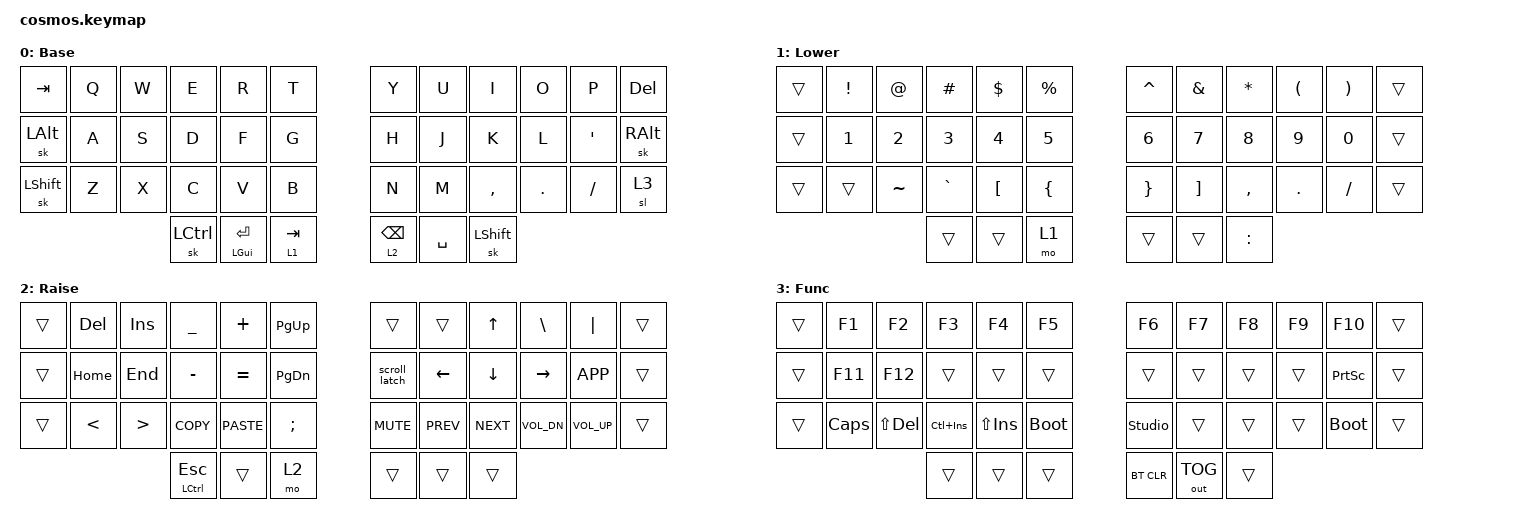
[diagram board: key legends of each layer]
#include <behaviors.dtsi>
#include <dt-bindings/zmk/keys.h>
#include <dt-bindings/zmk/bt.h>
#include <dt-bindings/zmk/outputs.h>

/ {
    behaviors {
        scroll_latch: scroll_latch {
            compatible = "cosmos,scroll-latch";
            #binding-cells = <0>;
            display-name = "Latch trackball scroll";
        };

        cosmos_unlock: cosmos_unlock {
            compatible = "cosmos,unlock";
            #binding-cells = <0>;
            display-name = "Private USB unlock";
        };

        // Thumb key behaviors from Mark Stosberg's layout
        gui_ent: gui_enter {
            compatible = "zmk,behavior-hold-tap";
            label = "GUI_ENTER";
            #binding-cells = <2>;
            flavor = "tap-preferred";
            tapping-term-ms = <200>;
            bindings = <&kp>, <&kp>;
        };

        low_tab: lower_tab {
            compatible = "zmk,behavior-hold-tap";
            label = "LOWER_TAB";
            #binding-cells = <2>;
            // Resolve Lower immediately when another key is pressed.
            flavor = "hold-preferred";
            tapping-term-ms = <200>;
            bindings = <&mo>, <&kp>;
        };

        rse_bsp: raise_backspace {
            compatible = "zmk,behavior-hold-tap";
            label = "RAISE_BACKSPACE";
            #binding-cells = <2>;
            // Resolve Raise on another key press; keep tap-then-hold Backspace repeat.
            flavor = "hold-preferred";
            tapping-term-ms = <200>;
            quick-tap-ms = <200>;
            bindings = <&mo>, <&kp>;
        };

        ctl_esc: control_escape {
            compatible = "zmk,behavior-hold-tap";
            label = "CONTROL_ESCAPE";
            #binding-cells = <2>;
            flavor = "tap-preferred";
            tapping-term-ms = <200>;
            bindings = <&kp>, <&kp>;
        };
    };

    combos {
        compatible = "zmk,combos";
        combo_unlock {
            timeout-ms = <200>;
            key-positions = <19 20 21>;
            bindings = <&cosmos_unlock>;
            layers = <3>;
        };
        combo_esc {
            timeout-ms = <50>;
            key-positions = <19 20>;
            bindings = <&kp ESC>;
            layers = <0>;
        };
    };

    keymap {
        compatible = "zmk,keymap";

        default_layer {
            display-name = "Base";
            bindings = <
                &kp TAB   &kp Q     &kp W     &kp E     &kp R     &kp T     &kp Y     &kp U     &kp I     &kp O     &kp P     &kp DEL
                &sk LALT  &kp A     &kp S     &kp D     &kp F     &kp G     &kp H     &kp J     &kp K     &kp L     &kp SQT   &sk RALT
                &sk LSHFT &kp Z     &kp X     &kp C     &kp V     &kp B     &kp N     &kp M     &kp COMMA &kp DOT   &kp SLASH &sl 3
                                    &sk LCTRL &gui_ent LGUI ENTER &low_tab 1 TAB &rse_bsp 2 BSPC &kp SPC   &sk LSHFT
            >;
        };

        lower_layer {
            display-name = "Lower";
            bindings = <
                &trans    &kp EXCL  &kp AT    &kp HASH  &kp DLLR  &kp PRCNT &kp CARET &kp AMPS  &kp ASTRK &kp LPAR  &kp RPAR  &trans
                &trans    &kp N1    &kp N2    &kp N3    &kp N4    &kp N5    &kp N6    &kp N7    &kp N8    &kp N9    &kp N0    &trans
                &trans    &trans    &kp TILDE &kp GRAVE &kp LBKT  &kp LBRC  &kp RBRC  &kp RBKT  &kp COMMA &kp DOT   &kp SLASH &trans
                                    &trans    &trans    &mo 1     &trans    &trans    &kp COLON
            >;
        };

        raise_layer {
            display-name = "Raise";
            // Inverted-T navigation: I up, J left, K down, L right.
            bindings = <
                &trans    &kp DEL   &kp INS   &kp UNDER &kp PLUS  &kp PG_UP &trans    &trans    &kp UP    &kp BSLH  &kp PIPE  &trans
                &trans    &kp HOME  &kp END   &kp MINUS &kp EQUAL &kp PG_DN &scroll_latch &kp LEFT &kp DOWN &kp RIGHT &kp K_APP &trans
                &trans    &kp LT    &kp GT    &kp K_COPY&kp K_PASTE&kp SEMI &kp K_MUTE &kp K_PREV &kp K_NEXT &kp K_VOL_DN &kp K_VOL_UP &trans
                                    &ctl_esc LCTRL ESC &trans    &mo 2     &trans    &trans    &trans
            >;
        };

        func_layer {
            display-name = "Func";
            bindings = <
                &trans    &kp F1    &kp F2    &kp F3    &kp F4    &kp F5    &kp F6    &kp F7    &kp F8    &kp F9    &kp F10   &trans
                &trans    &kp F11   &kp F12   &trans    &trans    &trans    &trans    &trans    &trans    &trans    &kp PRINTSCREEN &trans
                &trans    &kp CAPS  &kp LS(DEL) &kp LC(INS) &kp LS(INS) &bootloader   &studio_unlock &trans    &trans    &trans    &bootloader &trans
                                    &trans    &trans    &trans    &bt BT_CLR &out OUT_TOG &trans
            >;
        };
    };
};
